# f280013x_flash_ctrl_regs register map
Vendor: Texas Instruments
Peripheral module from a debugger description file (folder C2000).
Address unit: 16 bits
Registers are 32-bit, read-write, no defined reset value unless marked. A register's access mark holds for its fields unless they carry their own. Offsets are as the file gives them; lines under a group give offsets from that group; [hi:lo] are bit positions; {n}, {i} and the like mark numbered series; 'fields as' and 'values as' point back to an identical list; <NAME> marks a mode.

## FLASH_CTRL_REGS — FLASH CTRL Registers
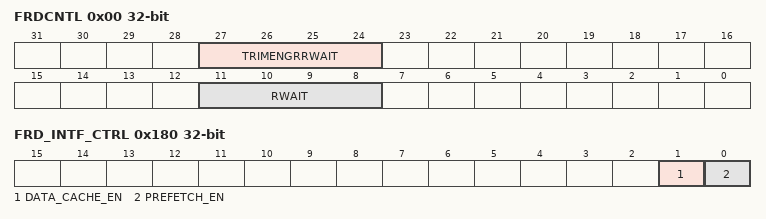
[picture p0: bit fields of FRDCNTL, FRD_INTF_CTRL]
0x00 FRDCNTL — Flash Read Control Register
  [27:24] TRIMENGRRWAIT — Random Read Waitstate of Trim and ENGR sectors.
  [11:8] RWAIT — Random Read Waitstate
0x04 FLPROT — Flash program/erase protect register
  [0] FLWEPROT — Flash write/erase protect bit.
0x40 FLCLKCTL — Flash NW clock control register.
  [3:0] KDIV — KDIV value of MCLK divider.
0x180 FRD_INTF_CTRL — Flash Read Interface Control Register
  [1] DATA_CACHE_EN — Data Cache Enable
  [0] PREFETCH_EN — Prefetch Enable
